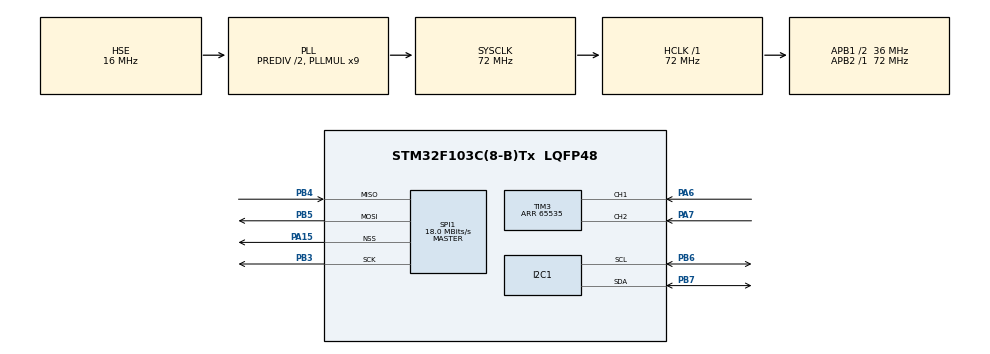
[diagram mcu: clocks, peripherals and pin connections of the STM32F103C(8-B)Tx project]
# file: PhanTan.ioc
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Mcu.Family=STM32F1
Mcu.Name=STM32F103C(8-B)Tx
Mcu.Package=LQFP48
NVIC.PriorityGroup=NVIC_PRIORITYGROUP_4
NVIC.TIM3_IRQn=true\:0\:0\:false\:false\:true\:true\:true
PA13.Mode=Serial_Wire
PA13.Signal=SYS_JTMS-SWDIO
PA14.Mode=Serial_Wire
PA14.Signal=SYS_JTCK-SWCLK
PA15.Mode=NSS_Signal_Hard_Output
PA15.Signal=SPI1_NSS
PA6.GPIO_PuPd=GPIO_PULLDOWN
PA6.Signal=S_TIM3_CH1
PA7.GPIO_PuPd=GPIO_PULLDOWN
PA7.Signal=S_TIM3_CH2
PB3.Mode=Full_Duplex_Master
PB3.Signal=SPI1_SCK
PB4.Mode=Full_Duplex_Master
PB4.Signal=SPI1_MISO
PB5.Mode=Full_Duplex_Master
PB5.Signal=SPI1_MOSI
PB6.Mode=I2C
PB6.Signal=I2C1_SCL
PB7.Mode=I2C
PB7.Signal=I2C1_SDA
PC14-OSC32_IN.Mode=LSE-External-Oscillator
PC14-OSC32_IN.Signal=RCC_OSC32_IN
PC15-OSC32_OUT.Mode=LSE-External-Oscillator
PC15-OSC32_OUT.Signal=RCC_OSC32_OUT
PD0-OSC_IN.Mode=HSE-External-Oscillator
PD0-OSC_IN.Signal=RCC_OSC_IN
PD1-OSC_OUT.Mode=HSE-External-Oscillator
PD1-OSC_OUT.Signal=RCC_OSC_OUT
ProjectManager.HeapSize=0x200
ProjectManager.StackSize=0x400
ProjectManager.TargetToolchain=STM32CubeIDE
RCC.AHBFreq_Value=72000000
RCC.APB1CLKDivider=RCC_HCLK_DIV2
RCC.APB1Freq_Value=36000000
RCC.APB1TimFreq_Value=72000000
RCC.APB2Freq_Value=72000000
RCC.APB2TimFreq_Value=72000000
RCC.EnbaleCSS=true
RCC.HCLKFreq_Value=72000000
RCC.HSEDivPLL=RCC_HSE_PREDIV_DIV2
RCC.HSE_VALUE=16000000
RCC.PLLMUL=RCC_PLL_MUL9
RCC.PLLSourceVirtual=RCC_PLLSOURCE_HSE
RCC.SYSCLKFreq_VALUE=72000000
RCC.SYSCLKSource=RCC_SYSCLKSOURCE_PLLCLK
RCC.USBFreq_Value=72000000
SH.S_TIM3_CH1.0=TIM3_CH1,Encoder_Interface
SH.S_TIM3_CH2.0=TIM3_CH2,Encoder_Interface
SPI1.BaudRatePrescaler=SPI_BAUDRATEPRESCALER_4
SPI1.CalculateBaudRate=18.0 MBits/s
SPI1.Direction=SPI_DIRECTION_2LINES
SPI1.FirstBit=SPI_FIRSTBIT_MSB
SPI1.Mode=SPI_MODE_MASTER
SPI1.VirtualNSS=VM_NSSHARD
SPI1.VirtualType=VM_MASTER
TIM3.EncoderMode=TIM_ENCODERMODE_TI2
TIM3.IC1Filter=10
TIM3.IC1Polarity=TIM_ICPOLARITY_RISING
TIM3.IC1Prescaler=TIM_ICPSC_DIV4
TIM3.IC2Filter=10
TIM3.IC2Polarity=TIM_ICPOLARITY_FALLING
TIM3.IC2Prescaler=TIM_ICPSC_DIV4
TIM3.Period=65535
board=custom

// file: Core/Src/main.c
/* USER CODE BEGIN Header */
/**
  ******************************************************************************
  * @file           : main.c
  * @brief          : Main program body
  ******************************************************************************
  * @attention
  *
  * <h2><center>&copy; Copyright (c) 2019 STMicroelectronics.
  * All rights reserved.</center></h2>
  *
  * This software component is licensed by ST under BSD 3-Clause license,
  * the "License"; You may not use this file except in compliance with the
  * License. You may obtain a copy of the License at:
  *                        opensource.org/licenses/BSD-3-Clause
  *
  ******************************************************************************
  */
/* USER CODE END Header */

#include "main.h"
#include "i2c.h"
#include "spi.h"
#include "tim.h"
#include "gpio.h"

void SystemClock_Config(void);

int main(void)
{

  /* MCU Configuration--------------------------------------------------------*/

  /* Reset of all peripherals, Initializes the Flash interface and the Systick. */
  HAL_Init();

  /* Configure the system clock */
  SystemClock_Config();

  /* Initialize all configured peripherals */
  MX_GPIO_Init();
  MX_I2C1_Init();
  MX_TIM3_Init();
  MX_SPI1_Init();
  /* USER CODE BEGIN 2 */

  /*initialize QMC5883L*/
  //QMC5883L_Init();

  //enable_TIM_counter();

  DWM1000_Init();

  /* USER CODE END 2 */

  /* Infinite loop */
  /* USER CODE BEGIN WHILE */
  while (1)
  {
	  //read_QMC5883L();

	  //read_RotaryEncoder();

	  DWM1000_exchange_data();

    /* USER CODE END WHILE */

  }
}

void SystemClock_Config(void)
{
  RCC_OscInitTypeDef RCC_OscInitStruct = {0};
  RCC_ClkInitTypeDef RCC_ClkInitStruct = {0};

  /** Initializes the CPU, AHB and APB busses clocks
  */
  RCC_OscInitStruct.OscillatorType = RCC_OSCILLATORTYPE_HSE;
  RCC_OscInitStruct.HSEState = RCC_HSE_ON;
  RCC_OscInitStruct.HSEPredivValue = RCC_HSE_PREDIV_DIV2;
  RCC_OscInitStruct.HSIState = RCC_HSI_ON;
  RCC_OscInitStruct.PLL.PLLState = RCC_PLL_ON;
  RCC_OscInitStruct.PLL.PLLSource = RCC_PLLSOURCE_HSE;
  RCC_OscInitStruct.PLL.PLLMUL = RCC_PLL_MUL9;
  if (HAL_RCC_OscConfig(&RCC_OscInitStruct) != HAL_OK)
  {
    Error_Handler();
  }
  /** Initializes the CPU, AHB and APB busses clocks
  */
  RCC_ClkInitStruct.ClockType = RCC_CLOCKTYPE_HCLK|RCC_CLOCKTYPE_SYSCLK
                              |RCC_CLOCKTYPE_PCLK1|RCC_CLOCKTYPE_PCLK2;
  RCC_ClkInitStruct.SYSCLKSource = RCC_SYSCLKSOURCE_PLLCLK;
  RCC_ClkInitStruct.AHBCLKDivider = RCC_SYSCLK_DIV1;
  RCC_ClkInitStruct.APB1CLKDivider = RCC_HCLK_DIV2;
  RCC_ClkInitStruct.APB2CLKDivider = RCC_HCLK_DIV1;

  if (HAL_RCC_ClockConfig(&RCC_ClkInitStruct, FLASH_LATENCY_2) != HAL_OK)
  {
    Error_Handler();
  }
  /** Enables the Clock Security System
  */
  HAL_RCC_EnableCSS();
}

void Error_Handler(void)
{
}

/************************ (C) COPYRIGHT STMicroelectronics *****END OF FILE****/
